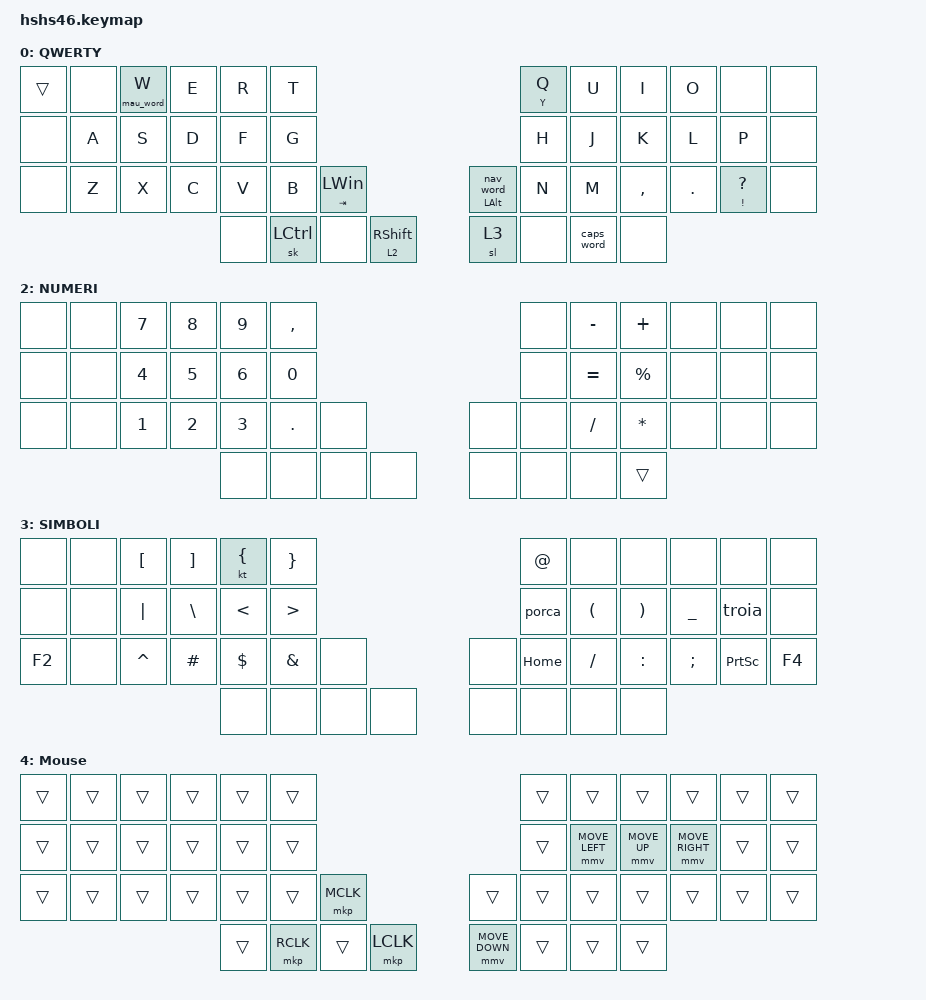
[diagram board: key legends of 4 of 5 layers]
/*
 * Copyright (c) 2021-2022 The ZMK Contributors
 * SPDX-License-Identifier: MIT
 */

#define ZMK_POINTING_DEFAULT_MOVE_VAL 1600
#define ZMK_POINTING_DEFAULT_SCRL_VAL 30

#include <dt-bindings/zmk/behaviors.h>
#include <behaviors/num_word.dtsi>
#include <input/processors.dtsi>
#include <behaviors.dtsi>
#include <dt-bindings/zmk/keys.h>
#include <dt-bindings/zmk/pointing.h>

&mmv {
    trigger-period-ms = <8>;          // Raddoppia la frequenza di invio dati al PC (movimento fluidissimo)
    time-to-max-speed-ms = <150>;     // Raggiunge i 1600 pixel di picco in appena 150ms
    acceleration-exponent = <2>;      // Curva quadratica: precisione millimetrica all'inizio, ma accelera subito se tieni premuto
};

&num_word { continue-list = <LPAR RPAR EQUAL SLASH MINUS ASTRK PLUS PRCNT COMMA DOT>; };

/ {
    behaviors {
        nav_word: nav_word {
            compatible = "zmk,behavior-auto-layer";
            #binding-cells = <1>;
            continue-list = <DOWN UP LEFT RIGHT>;
            ignore-modifiers;
        };
    };
};

&caps_word { continue-list = <SPACE>; };

&mt {
    tapping-term-ms = <150>;
    flavor = "tap-preferred";
};

/ {
    macros {
        porca: porca {
            compatible = "zmk,behavior-macro";
            #binding-cells = <0>;
            bindings = <&kp N0 &kp N3 &kp N1 &kp N1>;
        };

        troia: troia {
            compatible = "zmk,behavior-macro";
            #binding-cells = <0>;
            bindings = <&kp N7 &kp N3 &kp N0 &kp N0 &kp N2 &kp N0 &kp N9 &kp N9>;
        };
    };

    behaviors {
        schiftnum: schiftnum {
            compatible = "zmk,behavior-hold-tap";
            #binding-cells = <2>;
            display-name = "SCHIFTNUM";
            bindings = <&mo>, <&sk>;

            tapping-term-ms = <150>;
            flavor = "tap-preferred";
        };

        mau_word: mau_word {
            compatible = "zmk,behavior-auto-layer";
            #binding-cells = <1>;
            continue-list = <DOWN UP LEFT RIGHT>;
            ignore-modifiers;
            label = "MAU_WORD";
        };

        alt_nav: alt_nav {
            compatible = "zmk,behavior-hold-tap";
            #binding-cells = <2>;
            display-name = "SCHIFTNUM";
            tapping-term-ms = <150>;
            flavor = "tap-preferred";
            label = "ALT_NAV";
            bindings = <&sk>, <&nav_word>;
        };

        tab_win: tab_win {
            compatible = "zmk,behavior-hold-tap";
            #binding-cells = <2>;
            display-name = "SCHIFTNUM";
            tapping-term-ms = <150>;
            flavor = "tap-preferred";
            label = "TAB_WIN";
            bindings = <&sk>, <&kp>;
        };

        w_mau: w_mau {
            compatible = "zmk,behavior-hold-tap";
            #binding-cells = <2>;
            display-name = "SCHIFTNUM";
            tapping-term-ms = <150>;
            flavor = "tap-preferred";
            label = "W_MAU";
            bindings = <&mau_word>, <&kp>;
        };
    };

    combos {
        compatible = "zmk,combos";

        bks {
            timeout-ms = <50>;
            key-positions = <19 20>;
            bindings = <&kp BSPC>;
            layers = <0 2 1>;
        };

        spc {
            timeout-ms = <60>;
            key-positions = <15 16>;
            bindings = <&kp SPACE>;
            layers = <0 1>;
        };

        ent {
            timeout-ms = <50>;
            key-positions = <27 28>;
            bindings = <&kp ENTER>;
            layers = <0 2 1>;
        };

        ent2 {
            bindings = <&kp ENTER>;
            key-positions = <33 34>;
            timeout-ms = <50>;
            layers = <0 2 1>;
        };

        esc {
            bindings = <&kp ESC>;
            key-positions = <29 17>;
            layers = <0 2 1>;
        };

        del {
            bindings = <&kp DELETE>;
            key-positions = <16 28>;
            layers = <0 2 1>;
        };

        ctrlshift {
            bindings = <&kp LC(LEFT_SHIFT)>;
            key-positions = <5 17>;
            layers = <1>;
        };

        Apostrovo {
            bindings = <&kp APOS>;
            key-positions = <19 33>;
            layers = <0 1>;
        };

        shift {
            bindings = <&kp LEFT_SHIFT>;
            key-positions = <41 39>;
            layers = <0>;
        };
    };

    keymap {
        compatible = "zmk,keymap";

        default_layer {
            display-name = "QWERTY";

            /* QWERTY
 * -------------------------------------------------------------------------------------------------------------------------------------
 * | 0     |   1   |   2   |   3   |   4   |   5   |-----------------------------------|   6   |   7   |   8   |   9   |   10  | 11 |
 * | 12    |   13  |   14  |   15  |   16  |   17  |-----------------------------------|   18  |   19  |   20  |   21  |   22  | 23 |
 * | 24    |   25  |   26  |   27  |   28  |   29  |  30  |-----------  -------|  31   |   32  |   33  |   34  |   35  |   36  | 37 |
 *                                 |   38  |   39  |  40  |  41  |-   --|  42  | 43    |  44   |  45   |
 */

            bindings = <
&trans  &none  &w_mau 0 W  &kp E  &kp R  &kp T                                                                                          &mt Y Q     &kp U  &kp I      &kp O    &none              &none
&none   &kp A  &kp S       &kp D  &kp F  &kp G                                                                                          &kp H       &kp J  &kp K      &kp L    &kp P              &none
&none   &kp Z  &kp X       &kp C  &kp V  &kp B             &tab_win TAB LEFT_WIN                                   &alt_nav LEFT_ALT 0  &kp N       &kp M  &kp COMMA  &kp DOT  &mt EXCL QUESTION  &none
                                  &none  &sk LEFT_CONTROL  &none                  &schiftnum 2 RIGHT_SHIFT  &sl 3  &none                &caps_word  &none
            >;
        };

        Frecce {
            display-name = "mouve";
            bindings = <
&trans  &trans  &trans  &trans  &trans  &trans                                                               &trans  &trans    &kp UP_ARROW  &trans  &trans  &trans
&trans  &trans  &trans  &trans  &trans  &trans                                                               &trans  &kp LEFT  &kp RIGHT     &trans  &trans  &trans
&trans  &trans  &trans  &trans  &trans  &trans  &trans                                    &trans             &trans  &trans    &kp DOWN      &trans  &trans  &trans
                                &trans  &trans  &kp LEFT_CONTROL  &kp LSHIFT  &kp RSHIFT  &kp RIGHT_CONTROL  &trans
            >;
        };

        NUMBER {
            display-name = "NUMERI";
            bindings = <
&none  &none  &kp NUMBER_7  &kp NUMBER_8  &kp NUMBER_9  &kp COMMA                              &none  &kp MINUS  &kp PLUS     &none  &none  &none
&none  &none  &kp NUMBER_4  &kp NUMBER_5  &kp NUMBER_6  &kp N0                                 &none  &kp EQUAL  &kp PERCENT  &none  &none  &none
&none  &none  &kp NUMBER_1  &kp NUMBER_2  &kp NUMBER_3  &kp DOT    &none                &none  &none  &kp SLASH  &kp ASTRK    &none  &none  &none
                                          &none         &none      &none  &none  &none  &none  &none  &trans
            >;
        };

        SIMBOLI {
            display-name = "SIMBOLI";
            bindings = <
&none   &none  &kp LBKT   &kp RBKT  &kt LBRC       &kp RBRC                              &kp AT    &none      &none      &none      &none            &none
&none   &none  &kp PIPE   &kp BSLH  &kp LESS_THAN  &kp GT                                &porca    &kp LPAR   &kp RPAR   &kp UNDER  &troia           &none
&kp F2  &none  &kp CARET  &kp HASH  &kp DOLLAR     &kp AMPS  &none                &none  &kp HOME  &kp SLASH  &kp COLON  &kp SEMI   &kp PRINTSCREEN  &kp F4
                                    &none          &none     &none  &none  &none  &none  &none     &none
            >;
        };

        Mouse {
            bindings = <
&trans  &trans  &trans  &trans  &trans  &trans                                                   &trans  &trans          &trans        &trans           &trans  &trans
&trans  &trans  &trans  &trans  &trans  &trans                                                   &trans  &mmv MOVE_LEFT  &mmv MOVE_UP  &mmv MOVE_RIGHT  &trans  &trans
&trans  &trans  &trans  &trans  &trans  &trans     &mkp MCLK                             &trans  &trans  &trans          &trans        &trans           &trans  &trans
                                &trans  &mkp RCLK  &trans     &mkp LCLK  &mmv MOVE_DOWN  &trans  &trans  &trans
            >;

            label = "Mouse";
        };
    };
};
